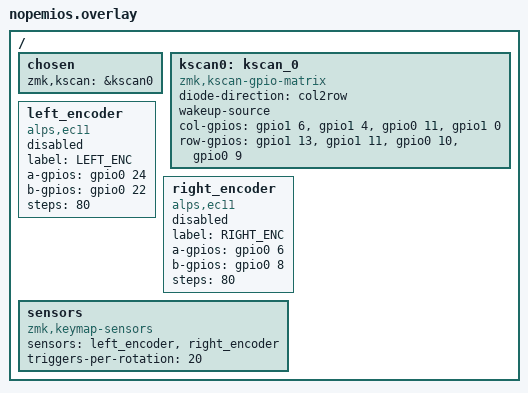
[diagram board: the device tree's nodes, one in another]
/ {
    chosen {
        zmk,kscan = &kscan0;
    };

    kscan0: kscan_0 {
        compatible = "zmk,kscan-gpio-matrix";
        diode-direction = "col2row";
        wakeup-source;

        col-gpios
            = <&gpio1 6 GPIO_ACTIVE_HIGH>
            , <&gpio1 4 GPIO_ACTIVE_HIGH>
            , <&gpio0 11 GPIO_ACTIVE_HIGH>
            , <&gpio1 0 GPIO_ACTIVE_HIGH>
            ;

        row-gpios
            = <&gpio1 13 (GPIO_ACTIVE_HIGH | GPIO_PULL_DOWN)>
            , <&gpio1 11 (GPIO_ACTIVE_HIGH | GPIO_PULL_DOWN)>
            , <&gpio0 10 (GPIO_ACTIVE_HIGH | GPIO_PULL_DOWN)>
            , <&gpio0 9 (GPIO_ACTIVE_HIGH | GPIO_PULL_DOWN)>
            ;
    };

        left_encoder: left_encoder {
            compatible = "alps,ec11";
            label = "LEFT_ENC";
            a-gpios = <&gpio0 24 (GPIO_ACTIVE_HIGH | GPIO_PULL_UP)>;
            b-gpios = <&gpio0 22 (GPIO_ACTIVE_HIGH | GPIO_PULL_UP)>;
            steps = <80>;
            status = "disabled";
        };

        right_encoder: right_encoder {
            compatible = "alps,ec11";
            label = "RIGHT_ENC";
            a-gpios = <&gpio0 6 (GPIO_ACTIVE_HIGH | GPIO_PULL_UP)>;
            b-gpios = <&gpio0 8 (GPIO_ACTIVE_HIGH | GPIO_PULL_UP)>;
            steps = <80>;
            status = "disabled";
        };

        sensors: sensors {
            compatible = "zmk,keymap-sensors";
            sensors = <&left_encoder &right_encoder>;
            triggers-per-rotation = <20>;
        };

};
